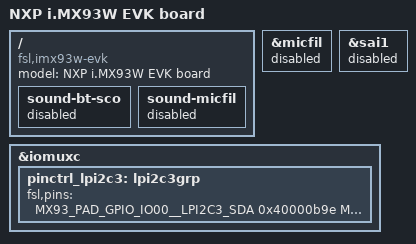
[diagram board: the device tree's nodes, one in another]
// SPDX-License-Identifier: (GPL-2.0+ OR MIT)
/*
 * Copyright 2025 NXP
 */

#include "../dts/upstream/src/arm64/freescale/imx93-11x11-evk.dts"

/ {
	model = "NXP i.MX93W EVK board";
	compatible = "fsl,imx93w-evk", "fsl,imx93";

	sound-bt-sco {
		status = "disabled";
	};

	sound-micfil {
		status = "disabled";
	};
};

&micfil {
	status = "disabled";
};

&sai1 {
	status = "disabled";
};

&iomuxc {
	pinctrl_lpi2c3: lpi2c3grp {
		fsl,pins = <
			MX93_PAD_GPIO_IO00__LPI2C3_SDA			0x40000b9e
			MX93_PAD_GPIO_IO01__LPI2C3_SCL			0x40000b9e
		>;
	};
};
